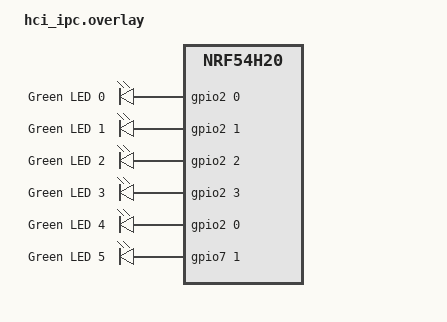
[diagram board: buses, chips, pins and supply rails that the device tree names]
/*
 * Copyright (c) 2024 Nordic Semiconductor ASA
 *
 * SPDX-License-Identifier: LicenseRef-Nordic-5-Clause
 */

#include "nrf54h20dk_nrf54h20_memory_map.dtsi"

&uart135 {
	status = "disabled";
};

&cpurad_rx_partitions {
	status = "okay";
};

/ {
	aliases {
		led0 = &led0;
		led1 = &led1;
		led2 = &led2;
		led3 = &led3;
		led4 = &led4;
		led5 = &led5;
	};

	leds {
		compatible = "gpio-leds";

		led0: led_0 {
			gpios = <&gpio2 0 GPIO_ACTIVE_HIGH>;
			label = "Green LED 0";
		};

		led1: led_1 {
			gpios = <&gpio2 1 GPIO_ACTIVE_HIGH>;
			label = "Green LED 1";
		};

		led2: led_2 {
			gpios = <&gpio2 2 GPIO_ACTIVE_HIGH>;
			label = "Green LED 2";
		};

		led3: led_3 {
			gpios = <&gpio2 3 GPIO_ACTIVE_HIGH>;
			label = "Green LED 3";
		};

		led4: led_4 {
			gpios = <&gpio2 0 GPIO_ACTIVE_HIGH>;
			label = "Green LED 4";
		};

		led5: led_5 {
			gpios = <&gpio7 1 GPIO_ACTIVE_HIGH>;
			label = "Green LED 5";
		};
	};
};

&gpiote130 {
	status = "okay";
	owned-channels = <7>;
	//interrupts = <104 NRF_DEFAULT_IRQ_PRIORITY>;
};

&gpio2 {
	status = "okay";
};

&gpio7 {
	status = "okay";
};
